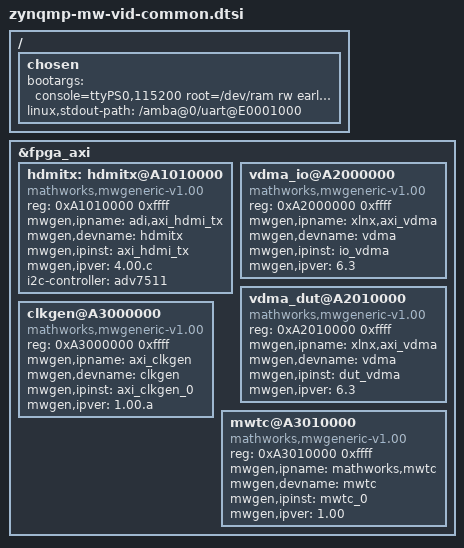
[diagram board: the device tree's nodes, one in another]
/{
	chosen {
		bootargs = "console=ttyPS0,115200 root=/dev/ram rw earlyprintk cma=128M";
		linux,stdout-path = "/amba@0/uart@E0001000";
	};
};

&fpga_axi{   
    hdmitx: hdmitx@A1010000 {
		compatible = "mathworks,mwgeneric-v1.00";
		reg = <0xA1010000 0xffff>;
		mwgen,ipname = "adi,axi_hdmi_tx";
		mwgen,devname = "hdmitx";
		mwgen,ipinst = "axi_hdmi_tx";
		mwgen,ipver = "4.00.c";
        i2c-controller = <&adv7511>;
	};
	
	vdma_io@A2000000 {
		compatible = "mathworks,mwgeneric-v1.00";
		reg = <0xA2000000 0xffff>;
		mwgen,ipname = "xlnx,axi_vdma";
		mwgen,devname = "vdma";
		mwgen,ipinst = "io_vdma";
		mwgen,ipver = "6.3";
	};
	vdma_dut@A2010000 {
		compatible = "mathworks,mwgeneric-v1.00";
		reg = <0xA2010000 0xffff>;
		mwgen,ipname = "xlnx,axi_vdma";
		mwgen,devname = "vdma";
		mwgen,ipinst = "dut_vdma";
		mwgen,ipver = "6.3";
	};
	clkgen@A3000000 {
		compatible = "mathworks,mwgeneric-v1.00";
		reg = <0xA3000000 0xffff>;
		mwgen,ipname = "axi_clkgen";
		mwgen,devname = "clkgen";
		mwgen,ipinst = "axi_clkgen_0";
		mwgen,ipver = "1.00.a";
	};
	mwtc@A3010000 {
		compatible = "mathworks,mwgeneric-v1.00";
		reg = <0xA3010000 0xffff>;
		mwgen,ipname = "mathworks,mwtc";
		mwgen,devname = "mwtc";
		mwgen,ipinst = "mwtc_0";
		mwgen,ipver = "1.00";
	};
};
